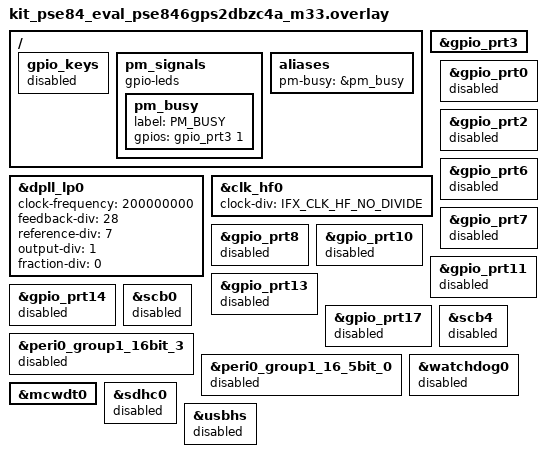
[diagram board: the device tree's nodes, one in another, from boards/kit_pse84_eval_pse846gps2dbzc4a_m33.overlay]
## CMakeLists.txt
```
cmake_minimum_required(VERSION 3.20.0)

# Register the app-local snippets/ dir so the `rram` snippet (used to
# link the image against the internal RRAM code region instead of the
# board-default SMIF XIP partition) is discoverable via
# `west build --snippet rram`. Must go BEFORE find_package(Zephyr) so
# snippets.cmake sees it during boilerplate include.
list(APPEND SNIPPET_ROOT ${CMAKE_CURRENT_SOURCE_DIR})

find_package(Zephyr REQUIRED HINTS $ENV{ZEPHYR_BASE})

project(pse84_m33_s_shell_ulp_lp_hp)

target_sources(app PRIVATE
    src/main.c
    src/power_manager.c
    src/power_manager_pll_retune.c
    src/power_manager_hf0_divider.c
    src/pm_phase_log.c
    src/pm_boot_optimize.c
    src/shell_cmds.c
    src/cmd_noidle.c
    src/cmd_sleep.c
    src/cmd_deep_sleep.c
    src/gpio_indicators.c
    src/diag.c
)

# When the `rram` snippet is selected, the SoC's signing helper
# (pse84_add_metadata_secure_hex) emits zephyr.signed.hex at the
# SMIF-SAHB base 0x60100000 for the m33-secure-only board variant
# (imgtool.py sign --hex-addr 0x60100000, derived from the board's
# `m33s_header` / `flash0_s` / `flash0_sahb` DT nodes).
# Rebase every IHEX extended-address record to RRAM-S 0x32011000
# (delta -0x2E0EF000) so OpenOCD's RRAM flash bank programs the
# correct memory. Payload bytes (vector table, MCUBoot header,
# hash, signature TLVs) are untouched, so SE-ROM signature
# verification still passes. Mirrors apps/00_hello_world, but note
# the base address differs by SoC variant: project 00 targets the
# m33/ns board where the signer picks 0x70100000; here we target
# the m33-secure-only board where it picks 0x60100000.
if("rram" IN_LIST SNIPPET_AS_LIST)
  set(_signed_hex ${ZEPHYR_BINARY_DIR}/${KERNEL_NAME}.signed.hex)
  set(_signed_hex_stamp ${_signed_hex}.rram.stamp)
  add_custom_command(
    OUTPUT ${_signed_hex_stamp}
    COMMAND ${CMAKE_COMMAND} -E echo
            "Shifting zephyr.signed.hex from SMIF-S 0x60100000 to RRAM-S 0x32011000"
    COMMAND ${CMAKE_OBJCOPY}
            --input-target=ihex
            --output-target=ihex
            --change-addresses=-0x2E0EF000
            ${_signed_hex}
            ${_signed_hex}.tmp
    COMMAND ${CMAKE_COMMAND} -E rename ${_signed_hex}.tmp ${_signed_hex}
    COMMAND ${CMAKE_COMMAND} -E touch ${_signed_hex_stamp}
    DEPENDS ${_signed_hex}
    COMMENT "Retargeting zephyr.signed.hex SMIF-S -> RRAM-S"
  )
  add_custom_target(retarget_signed_hex_to_rram ALL
    DEPENDS ${_signed_hex_stamp}
  )
endif()
```

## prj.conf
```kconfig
# Zephyr shell over the SCB UART console.
CONFIG_SHELL=y

# Shell serial backend: IRQ-driven RX. This lets the CPU stay in WFI
# indefinitely while waiting for a keypress, instead of polling the
# UART FIFO every CONFIG_SHELL_BACKEND_SERIAL_RX_POLL_PERIOD ms (10 ms
# default) which produces a visible 100 Hz spike train on the PPK2
# rail and keeps the "idle" baseline artificially elevated.
#
# HISTORICAL NOTE: an earlier revision of this project pinned the
# backend to CONFIG_SHELL_BACKEND_SERIAL_API_POLLING because the
# Infineon SCB UART driver's IRQ path spun forever on the first RX
# byte (Unhandled IRQn: 121 / bt_uart_isr hang, see
# doc/ifx_uart_driver_bug.md). That bug has since been fixed in
# zephyr/drivers/serial/uart_infineon_pdl.c
# (ifx_cat1_uart_irq_update now W1Cs RX_NOT_EMPTY and RX/TX error
# latches). The IRQ backend is now the correct choice.
CONFIG_UART_INTERRUPT_DRIVEN=y
CONFIG_SHELL_BACKEND_SERIAL_API_INTERRUPT_DRIVEN=y

# Enable the ARM idle-entry hook so the `noidle` shell command can
# veto WFI in the idle thread. When noidle is on, the CPU spin-loops
# through arch_cpu_idle() instead of sleeping -- lets us measure
# real active current at HP/LP/ULP, and gives the upcoming `sleep`
# command a non-sleeping baseline to compare against.
#
# ARM_ON_ENTER_CPU_IDLE_HOOK is a promptless symbol -- the app-local
# Kconfig defines APP_ENABLE_IDLE_HOOK which selects it.
CONFIG_APP_ENABLE_IDLE_HOOK=y

# Shell size trims to fit the 63 KB RRAM code region (rram snippet).
# We only need three top-level commands (hp / lp / ulp); help text,
# tab-completion, VT100 escapes and command history all cost ~1-2 KB
# each in RRAM and are not required for this demo.
CONFIG_SHELL_HELP=n
CONFIG_SHELL_HISTORY=n
CONFIG_SHELL_METAKEYS=n
CONFIG_SHELL_VT100_COMMANDS=n
CONFIG_SHELL_TAB=n
CONFIG_SHELL_TAB_AUTOCOMPLETION=n

# GPIO for the three on-board RGB indicator LEDs used by the shell
# handlers to signal the incoming mode before the SoC starts changing
# clocks / voltage.
CONFIG_GPIO=y

# Main stack: 4 KiB gives plenty of headroom for the LP/ULP transition
# code path which unrolls Cy_SysPm_SystemEnter{Hp,Lp,Ulp} + RRAM +
# ClkHf writes plus their PDL callback lists.
CONFIG_MAIN_STACK_SIZE=4096

# --- System timer ------------------------------------------------------
# Use the Infineon LPTIMER (MCWDT0 on PILO @ 32.768 kHz) as the Zephyr
# system clock instead of Cortex-M SysTick.
#
# SysTick is clocked from HF0 (the CPU clock), which this build
# reprograms per HP/LP/ULP mode (200 / 66 / 50 MHz). SysTick counts
# would then scale by the same ratio, making k_msleep / k_timer /
# k_cycle_get_32 report ~3-4x too long at LP/ULP -- see the (now
# retired) OPEN_systick_hf0_scaling.md analysis. MCWDT0 runs from
# PILO which is independent of every HF clock and stays alive through
# CPU deep sleep too, so it doubles as a deep-sleep wake source.
#
# The LPTIMER PDL driver (infineon_lp_timer_pdl.c) auto-enables via
# default y once mcwdt0 is 'okay' in DT. We just need to turn SysTick
# off so there is only one system-clock provider at link time.
CONFIG_CORTEX_M_SYSTICK=n
CONFIG_INFINEON_LP_TIMER_PDL=y
CONFIG_SYS_CLOCK_HW_CYCLES_PER_SEC=32768
```

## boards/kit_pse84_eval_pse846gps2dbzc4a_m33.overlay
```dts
/*
 * Copyright (c) 2026
 * SPDX-License-Identifier: Apache-2.0
 *
 * Minimal DT overlay for apps/06_pse84_m33_s_shell_ulp_lp_hp.
 *
 * Kept enabled (from the board common.dtsi / kit_pse84_eval_m33.dts):
 *   scb2 (uart2)              -> zephyr,console + zephyr,shell-uart
 *   peri0_group1_16bit_1      -> scb2 peripheral clock divider
 *   gpio_prt16                -> RGB LEDs (led0..led2 on P16.5-7)
 *   gpio_prt3                 -> pm_busy scope trigger on P3.1
 *   flash_controller / rram0  -> code storage (--snippet rram redirects
 *                                zephyr,flash here)
 *
 * Clock-tree baseline (see PLAN_dual_dvfs.md for full rationale)
 * ---------------------------------------------------------------
 * DPLL_LP0 is retuned to 200 MHz (from the board default 400 MHz)
 * and CLK_HF0 is set to divide-by-1, so:
 *
 *   DPLL_LP0 = 200 MHz
 *     |-- CLK_HF0  (/1)  = 200 MHz  -> CM33 core, AN237976 HP max
 *     `-- CLK_HF10 (/4)  =  50 MHz  -> SCB2 peripheral clock
 *
 * Reasons for this baseline:
 *   1. CM33 lands at exactly the AN237976 HP spec ceiling from boot,
 *      no runtime action needed.
 *   2. The maximum DPLL frequency ever seen at runtime is 200 MHz,
 *      safely inside DPLL_LP's 10-500 MHz spec at every voltage --
 *      the 400 MHz baseline previously flirted with the ULP-voltage
 *      lock hazard whenever the PLL-retune path had to reprogram
 *      it back up.
 *   3. Both DVFS approaches (PLL-retune and divider-only, see
 *      PLAN_dual_dvfs.md) share this same baseline so a switch
 *      between them is a code-only change.
 */

#include <zephyr/dt-bindings/clock/ifx_clock_source_common.h>

/ {
	/* Disable the gpio-keys container so the user button (P8.3)
	 * doesn't drag in gpio_prt8. The child node stays defined so
	 * DT_ALIAS(sw0) remains resolvable (evaluates disabled). */
	gpio_keys { status = "disabled"; };

	/* PM-transition scope trigger. P3.1 is driven high by the shell
	 * command layer while a mode change is in progress and low
	 * again once the transition (including SCB retune + clock
	 * probe) has completed. Wire a scope / logic-analyzer probe
	 * here to correlate current-draw waveforms with the actual
	 * software transition window. */
	pm_signals {
		compatible = "gpio-leds";
		pm_busy: pm_busy {
			label = "PM_BUSY";
			gpios = <&gpio_prt3 1 GPIO_ACTIVE_HIGH>;
		};
	};

	aliases {
		pm-busy = &pm_busy;
	};
};

/* Enable gpio_prt3 -- disabled at the SoC-dtsi level, but we need
 * it to drive the pm_busy scope trigger on P3.1 (see pm_signals
 * above). */
&gpio_prt3 { status = "okay"; };

/* ------------------------------------------------------------------
 * DPLL_LP0 -- retune the board default from 400 MHz to 200 MHz.
 *
 * Formula: output = input * feedback-div / (reference-div * output-div)
 * Input on this board is IHO = 50 MHz. Board default (400 MHz) uses
 * FB=56, REF=7, OUT=1 -> 50 * 56 / (7 * 1) = 400. Halving FB to 28
 * gives 50 * 28 / (7 * 1) = 200 MHz. Reference-div stays 7 to keep
 * the same phase-noise / jitter profile the board vendor selected.
 * ------------------------------------------------------------------ */
&dpll_lp0 {
	clock-frequency = <200000000>;
	feedback-div = <28>;
	reference-div = <7>;
	output-div = <1>;
	fraction-div = <0>;
};

&clk_hf0 {
	/* /1: DPLL_LP0 (200 MHz) -> CLK_HF0 200 MHz.
	 * Matches AN237976 CM33 HP frequency spec. The board default
	 * is /2 (was correct when DPLL was 400 MHz); we override to /1
	 * now that DPLL is at 200 MHz so the same baseline works for
	 * both DVFS approaches (see PLAN_dual_dvfs.md). */
	clock-div = <IFX_CLK_HF_NO_DIVIDE>;
};

/* ------------------------------------------------------------------
 * GPIO ports: keep only gpio_prt16 (RGB LEDs) and gpio_prt3 (see
 * the pm_signals node above -- P3.1 is the pm_busy scope trigger).
 * SCB2 pins (P6.5/P6.7) are routed by the pinctrl subsystem and do
 * NOT require the gpio_prt6 node to be enabled -- the pinctrl
 * driver programs HSIOM directly.
 * ------------------------------------------------------------------ */
&gpio_prt0  { status = "disabled"; };
&gpio_prt2  { status = "disabled"; };
&gpio_prt6  { status = "disabled"; };
&gpio_prt7  { status = "disabled"; };
&gpio_prt8  { status = "disabled"; };
&gpio_prt10 { status = "disabled"; };
&gpio_prt11 { status = "disabled"; };
&gpio_prt13 { status = "disabled"; };
&gpio_prt14 { status = "disabled"; };
&gpio_prt17 { status = "disabled"; };

/* ------------------------------------------------------------------
 * SCBs we don't use.
 * ------------------------------------------------------------------ */
&scb0 { status = "disabled"; };   /* i2c0 + bmi270 accelerometer   */
&scb4 { status = "disabled"; };   /* uart4 + bt_hci_uart + cyw55513 */

/* Their peripheral clock dividers -- also unused. */
&peri0_group1_16bit_3   { status = "disabled"; };  /* scb0 clock */
&peri0_group1_16_5bit_0 { status = "disabled"; };  /* scb4 clock */

/* ------------------------------------------------------------------
 * Timers, watchdogs, storage, connectivity we don't use.
 * ------------------------------------------------------------------ */
&watchdog0 { status = "disabled"; };

/* mcwdt0 is the Zephyr system-timer for this build (LPTIMER driver,
 * infineon_lp_timer_pdl.c). Runs off PILO @ 32.768 kHz, independent
 * of HF0, so k_msleep and k_cycle_get_32 do NOT scale with the
 * HP/LP/ULP mode -- fixes OPEN_systick_hf0_scaling.md. Also gives
 * `sleep` / `deep_sleep` shell commands a mode-independent wake
 * source (MCWDT keeps counting through CPU deep sleep too, because
 * PILO is a deep-sleep-alive clock). */
&mcwdt0    { status = "okay"; };
&sdhc0     { status = "disabled"; };   /* SDIO + airoc-wifi */
&usbhs     { status = "disabled"; };
```

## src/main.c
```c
/*
 * Copyright (c) 2026
 * SPDX-License-Identifier: Apache-2.0
 *
 * CM33-Secure shell-controlled active-power-mode demo -- bring-up.
 *
 * This file only handles application bring-up: print a banner,
 * initialise the GPIO indicators, initialise the power-mode
 * manager. Everything else lives in dedicated modules:
 *
 *   src/power_manager.[ch]   -- HP/LP/ULP transitions, PLL retune,
 *                               clock-measurement probe.
 *   src/shell_cmds.[ch]      -- ulp / lp / hp / probe shell
 *                               handlers.
 *   src/gpio_indicators.[ch] -- mode-indicator LEDs (led0 red,
 *                               led1 green) + PM-busy scope
 *                               trigger on P3.1.
 *   src/diag.[ch]            -- raw-SCB tracing, blue-LED
 *                               heartbeat thread (led2).
 *
 * The Zephyr shell auto-registers commands via SHELL_CMD_REGISTER
 * at link time, so pulling shell_cmds.c into the build is enough
 * to make the commands available.
 */

#include <stdio.h>

#include <zephyr/kernel.h>

#include "gpio_indicators.h"
#include "power_manager.h"

int main(void)
{
	printf("CM33-S shell-power-mode on %s\n", CONFIG_BOARD);

	if (gpio_indicators_init() < 0) {
		printf("CM33-S: GPIO indicators init failed\n");
		/* Non-fatal: shell + mode transitions still work; only
		 * the visual LED indicators and the P3.1 scope trigger
		 * are dark. */
	}

	pm_init();

	printf("CM33-S: initial power mode %s\n",
	       pm_mode_name(pm_current_mode()));
	return 0;
}
```

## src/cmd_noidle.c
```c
/*
 * Copyright (c) 2026
 * SPDX-License-Identifier: Apache-2.0
 */

/**
 * @file
 * @brief `noidle` shell command + Zephyr idle-hook to suppress WFI.
 *
 * Motivation: on this build the Zephyr idle thread runs
 * @c arch_cpu_idle() which normally does @c __WFI(). That means
 * "shell prompt idle" current on the PPK2 is already CPU-sleep
 * current -- WFI is happening whenever no thread has work.
 *
 * For a DVFS demo we sometimes want to see the OPPOSITE: what
 * does the SoC pull when the CM33 is genuinely executing code
 * (fetching, decoding, executing) at 200 / 80 / 50 MHz? That is
 * the delta the "sleep" command will reclaim, and without a way
 * to force the CPU into that state on demand there is nothing to
 * compare against.
 *
 * Zephyr exposes exactly this knob via @c CONFIG_ARM_ON_ENTER_CPU_IDLE_HOOK.
 * When enabled, the arch layer calls @c z_arm_on_enter_cpu_idle()
 * right before it would execute WFI. Returning @c false skips
 * WFI entirely -- the idle thread then just spin-loops through
 * @c arch_cpu_idle() returning immediately, and higher-priority
 * threads (or ISRs) still preempt as usual.
 *
 * Shell interface:
 *
 *   noidle          -- print current state ("on" or "off")
 *   noidle on       -- suppress WFI in idle. CPU runs continuously
 *                      at the current HP/LP/ULP mode clock rate.
 *                      PPK2 shows the real active current for
 *                      that mode.
 *   noidle off      -- restore normal WFI in idle. This is the
 *                      default state at boot. PPK2 shows the
 *                      sleep floor plus whatever the workqueue /
 *                      housekeeping wakes cost.
 *
 * Nothing else in this project queries the flag -- the hook is
 * the only consumer. Made @c atomic_t so a stray future concurrent
 * writer is well-defined; the hook itself runs from the idle
 * thread and cannot be preempted by another writer today.
 */

#include <zephyr/init.h>
#include <zephyr/kernel.h>
#include <zephyr/shell/shell.h>
#include <zephyr/sys/atomic.h>

#include <stddef.h>

/**
 * @brief When non-zero, @c z_arm_on_enter_cpu_idle returns false
 *        and the idle thread's WFI is skipped.
 */
static atomic_t s_prevent_idle;

/**
 * @brief ARM idle-entry hook (enabled by CONFIG_ARM_ON_ENTER_CPU_IDLE_HOOK).
 *
 * Called from @c arch_cpu_idle() with interrupts already disabled
 * via PRIMASK and BASEPRI set to 0. Return @c true to let the WFI
 * run (default), @c false to bypass it and return immediately.
 *
 * Keeping the check as a single atomic-read means no lock, no
 * branch predictor surprise, and the hook itself costs a handful
 * of cycles per idle entry -- negligible next to the WFI it
 * gates.
 */
bool z_arm_on_enter_cpu_idle(void)
{
	return atomic_get(&s_prevent_idle) == 0;
}

/**
 * @brief Shell handler for `noidle [on|off]`.
 *
 * With no argument, reports the current state. With "on" or
 * "off", sets it. Any other argument is a syntax error.
 */
static int cmd_noidle(const struct shell *sh, size_t argc, char **argv)
{
	if (argc == 1) {
		shell_print(sh, "noidle is %s",
			    (atomic_get(&s_prevent_idle) != 0) ? "on" : "off");
		return 0;
	}

	if (argc != 2) {
		shell_error(sh, "usage: noidle [on|off]");
		return -EINVAL;
	}

	if (strcmp(argv[1], "on") == 0) {
		atomic_set(&s_prevent_idle, 1);
		shell_print(sh, "noidle on -- CPU spins in idle (no WFI)");
		return 0;
	}
	if (strcmp(argv[1], "off") == 0) {
		atomic_set(&s_prevent_idle, 0);
		shell_print(sh, "noidle off -- WFI in idle (default)");
		return 0;
	}

	shell_error(sh, "usage: noidle [on|off]");
	return -EINVAL;
}

SHELL_CMD_REGISTER(noidle, NULL,
		   "Suppress WFI in idle thread. Use `noidle on` to see real "
		   "active current at the current HP/LP/ULP mode.",
		   cmd_noidle);
```

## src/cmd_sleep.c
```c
/*
 * Copyright (c) 2026
 * SPDX-License-Identifier: Apache-2.0
 */

/**
 * @file
 * @brief `sleep` shell command -- put CM33 into CPU-sleep (WFI) until
 *        the next NVIC IRQ (typically a UART RX character).
 *
 * Motivation: with `noidle on` the CPU spin-loops in idle and pulls
 * the mode's real active current (HP 5.36 / LP 2.34 / ULP 1.54 mA
 * measured). Running an explicit `sleep` puts the core into WFI on
 * demand and drops the current back to the sleep floor (HP 3.34 /
 * LP 1.73 / ULP 1.16 mA measured) until a keypress. Together with
 * `noidle`, the pair gives an on-demand active-vs-sleep A/B
 * measurement without waiting for Zephyr's idle thread to decide.
 *
 * Cycle instrumentation: reads @c k_cycle_get_32 (which on this SoC
 * is @c Cy_MCWDT_GetCountCascaded (counter2 @ 50 MHz LPTIMER)) both
 * sides of the @c __WFI. The delta is wall-clock time -- the CPU
 * pipeline was stopped, but the LPTIMER runs off HF10 (independent
 * of HF0). This is the number PPK2's D7 sees as the sleep window
 * width.
 *
 * pm-busy GPIO framing so external post-processing (PPK2 + D7 line)
 * can locate the WFI window automatically:
 *
 *   pm-busy HIGH       cmd running (banner print + TX drain, ~20 ms)
 *   pm-busy LOW        WFI window (variable duration -- user waits,
 *                                  presses key, chip wakes)
 *   pm-busy HIGH       post-wake (elapsed print, ~1 ms)
 *   pm-busy LOW        back to shell prompt
 *
 * IRQ prologue mirrors tmp/16_pse84_3img_rram_pm/m33_ns/src/power.c:
 * PRIMASK on, BASEPRI off, so the CPU still wakes on any enabled
 * NVIC source but interrupts don't actually take (they just pend
 * and get serviced after __enable_irq). Without this, WFI can
 * either miss the wake (BASEPRI masks the source out) or run the
 * ISR mid-instrumentation (jitters the cycle count).
 *
 * Break-even relative to `noidle on`:
 *   The entry/exit overhead is dominated by shell_print + k_msleep
 *   (tens of ms) which is a demo-only cost. The interesting number
 *   is the WFI entry/exit itself: on Cortex-M33 that is a handful
 *   of CPU cycles either side of the instruction (order 10 ns at
 *   200 MHz). At any HP/LP/ULP active-vs-sleep delta above ~0.4 mA,
 *   break-even is under 1 us. That is: any sleep window longer than
 *   ~1 us is a net energy win. Post-processing table quantifies
 *   this per mode.
 */

#include <zephyr/kernel.h>
#include <zephyr/shell/shell.h>
#include <zephyr/sys/time_units.h>

#include <cmsis_core.h>
#include <cy_sysclk.h>

#include <stddef.h>

#include "gpio_indicators.h"

/**
 * @brief Shell handler for `sleep`.
 *
 * Blocks the shell thread on WFI until the next NVIC interrupt.
 * The chip's UART RX IRQ is enabled and unmasked, so any character
 * typed in the terminal wakes the CPU. Other enabled ISRs
 * (LPTIMER, workqueue) may also wake spuriously; the printed
 * duration lets the user distinguish "keypress wake" (100+ ms) from
 * "housekeeping wake" (~80 ms periodic on this build).
 */
static int cmd_sleep(const struct shell *sh, size_t argc, char **argv)
{
	ARG_UNUSED(argc);
	ARG_UNUSED(argv);

	/* Mark: sleep command is running (pm-busy HIGH). */
	gpio_indicators_transition_begin();

	shell_print(sh, "entering CPU sleep -- press any key to wake");

	/* Let the shell TX ring drain before WFI. In IRQ-driven mode
	 * the TX-empty IRQ would spuriously wake us mid-drain; a
	 * short sleep here yields to that IRQ path via the idle
	 * thread (which itself still WFIs -- noidle only affects
	 * arch_cpu_idle, not k_sleep) and returns once the shell TX
	 * is quiescent. 20 ms is enough for ~200 chars at 115200 8N1. */
	k_msleep(20);

	/* Mark: about to WFI (pm-busy HIGH -> LOW). Post-processing
	 * uses this falling edge as the sleep-window start. */
	gpio_indicators_transition_end();

	uint32_t t_enter = k_cycle_get_32();

	/* PRIMASK on, BASEPRI off -- see file-level comment. */
	__disable_irq();
	irq_unlock(0);
	__DSB();
	__WFI();
	__enable_irq();

	uint32_t t_exit = k_cycle_get_32();

	/* Mark: woke up (pm-busy LOW -> HIGH). Post-processing uses
	 * this rising edge as the sleep-window end. */
	gpio_indicators_transition_begin();

	uint32_t dwell_cyc = t_exit - t_enter;

	/* IMPORTANT: k_cycle_get_32 reads Cortex-M SysTick, which is
	 * clocked from HF0 (the CPU clock). This build reprograms HF0
	 * per mode (HP=200 / LP=66 / ULP=50 MHz), but Zephyr's
	 * CONFIG_SYS_CLOCK_HW_CYCLES_PER_SEC is a compile-time constant
	 * baked at HP. Using k_cyc_to_us_floor32 here would mis-report
	 * dwell by up to 4x. Convert against the LIVE HF0 frequency
	 * instead, read from the PDL at print time.
	 *
	 * Broader impact (not fixed here): every Zephyr timer function
	 * -- k_msleep, k_sleep, k_timer, thread timeouts -- is scaled
	 * by the same wrong factor at LP/ULP. That is why the
	 * "mysterious 80 ms periodic wake" observed at LP is really
	 * Zephyr's ~26 ms housekeeping tick stretched by the HF0
	 * ratio. Fix belongs in the system-timer selection (use
	 * MCWDT0/LPTIMER on HF10 which is constant across modes).
	 * Tracked separately. */
	uint32_t hf0_hz = Cy_SysClk_ClkHfGetFrequency(0U);
	uint32_t dwell_us =
	    (uint32_t)(((uint64_t)dwell_cyc * 1000000U) / hf0_hz);

	shell_print(sh, "woke after %u us (%u cycles @ live HF0 = %u Hz)",
		    dwell_us, dwell_cyc, hf0_hz);

	/* Mark: shell prompt returning (pm-busy HIGH -> LOW). */
	gpio_indicators_transition_end();
	return 0;
}

SHELL_CMD_REGISTER(sleep, NULL,
		   "Enter CPU sleep (WFI) until any NVIC IRQ (e.g. UART RX). "
		   "Prints wall-clock dwell on wake. Pair with `noidle on` "
		   "to see the active-vs-sleep current delta.",
		   cmd_sleep);
```

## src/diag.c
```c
/*
 * Copyright (c) 2026
 * SPDX-License-Identifier: Apache-2.0
 *
 * See diag.h for the diagnosis matrix and rationale.
 */

#include "diag.h"

#include <stdint.h>

#include <zephyr/device.h>
#include <zephyr/drivers/gpio.h>
#include <zephyr/kernel.h>

/*
 * SCB2 register block base. Hard-coded rather than derived from DT
 * because we deliberately want to poke this SCB even when the Zephyr
 * driver's cached configuration might be broken.
 *
 * PSE84 exposes SCB2 through two AHB aliases; the correct one depends
 * on the security state of the accessing bus master:
 *
 *   Non-Secure alias (M33-NS / M55-NS code):  0x429a0000
 *   Secure     alias (M33-S code):            0x529a0000
 *
 * This project builds for `kit_pse84_eval/pse846gps2dbzc4a/m33` (the
 * Secure-only board variant, CONFIG_TRUSTED_EXECUTION_SECURE=y), so
 * we MUST use the Secure alias. Writing the NS alias from Secure
 * code raises a BusFault (\"peripheral not accessible from current
 * security state\") that escalates to HardFault -- observed as the
 * whole CPU freezing on the very first diag_trace() call, the
 * heartbeat thread never getting to run, and no bytes on the wire.
 *
 * The pse84_s.dtsi node confirms the mapping:
 *   scb2: scb@529a0000 { reg = <0x529a0000 0xfd0>; ... }
 *
 * Note: the reference implementation
 * `tmp/zephyr_dvfs_dpm_proposed/common/pse84_aliases.h` hard-codes
 * 0x429a0000 because that project's raw-console lives in CM33-NS.
 *
 * SCB register offsets from Infineon `pdl/devices/include/ip/cyip_scb.h`
 * (verified: TX_FIFO_STATUS at 0x208, TX_FIFO_WR at 0x240 -- these
 * are IP-version-stable on the PSE84 SCB v3):
 *   TX_FIFO_STATUS  0x208   bits[8:0]  = USED entry count
 *                           bit  15    = SR_VALID (TX shift reg has a byte)
 *   TX_FIFO_WR      0x240   write here to enqueue a byte
 *
 * Earlier revisions of this file tried to use INTR_TX.UART_DONE
 * (offset 0xF80, bit 9) for the "TX complete" check. UART_DONE is a
 * LATCHED interrupt bit -- it only re-asserts on the transition
 * from "TX busy" to "TX idle". If the FIFO is already empty when
 * diag_trace_flush() is called (which is the norm at the end of
 * pm_switch_to, because pm_pll_reconfigure() flushed inside the
 * callback and nothing else was queued in the meantime), UART_DONE
 * never transitions and the flush spins forever, freezing the
 * console.
 *
 * TX_FIFO_STATUS.{USED, SR_VALID} are STATE bits, not latches --
 * safe to poll unconditionally. This mirrors the PDL helper
 * Cy_SCB_IsTxComplete() which uses exactly these two fields.
 */
#define APP_SCB2_BASE 0x529a0000u
#define APP_SCB2_TX_FIFO_STATUS (*(volatile uint32_t *)(APP_SCB2_BASE + 0x208u))
#define APP_SCB2_TX_FIFO_WR (*(volatile uint32_t *)(APP_SCB2_BASE + 0x240u))

/* From cyip_scb.h SCB_TX_FIFO_STATUS_{USED,SR_VALID}_Msk -- exposed
 * here as local constants so the raw-SCB path stays completely
 * independent of the PDL. */
#define APP_SCB2_TX_FIFO_STATUS_USED_Msk 0x000001FFu
#define APP_SCB2_TX_FIFO_STATUS_SR_VALID_Msk 0x00008000u

/*
 * SCB v3 TX FIFO on PSE84 is 256 entries deep, but the block is
 * initialised with a smaller effective depth. Waiting until USED
 * drops below 16 leaves plenty of headroom and matches the reference
 * implementation's threshold.
 */
#define APP_SCB2_TX_FIFO_HEADROOM 16u

void diag_trace_char(char c)
{
	while ((APP_SCB2_TX_FIFO_STATUS & APP_SCB2_TX_FIFO_STATUS_USED_Msk) >=
	       APP_SCB2_TX_FIFO_HEADROOM) {
		/* spin — wait for TX FIFO room */
	}
	APP_SCB2_TX_FIFO_WR = (uint32_t)(uint8_t)c;
}

void diag_trace(const char *s)
{
	if (s == NULL) {
		return;
	}
	while (*s != '\0') {
		if (*s == '\n') {
			diag_trace_char('\r');
		}
		diag_trace_char(*s);
		s++;
	}
}

void diag_trace_flush(void)
{
	/* Wait until both the TX FIFO and the shift register are empty.
	 * Both fields live in TX_FIFO_STATUS -- one register read per
	 * loop iteration. Naturally returns immediately if the SCB is
	 * already idle, because both fields are true state (not latches
	 * that need a fresh transition to re-arm). Equivalent to the
	 * PDL's Cy_SCB_IsTxComplete(). */
	const uint32_t busy_mask = APP_SCB2_TX_FIFO_STATUS_USED_Msk |
				   APP_SCB2_TX_FIFO_STATUS_SR_VALID_Msk;

	while ((APP_SCB2_TX_FIFO_STATUS & busy_mask) != 0u) {
		/* spin */
	}
}

/*
 * Heartbeat thread ---------------------------------------------------
 *
 * Owns led2 (blue) exclusively so its blink rate is a pure indicator
 * of CPU liveness. Independent of console, Zephyr shell backend, and
 * any mode-transition side-effect. If the blue LED continues blinking
 * at ~2 Hz after a console "freeze", the CPU is still executing
 * scheduled threads — the fault must be in the console path (Zephyr
 * shell task, SCB UART driver, or the shell's ring-buffer).
 *
 * Uses a low-priority preemptible thread so it never starves the
 * shell RX / TX handlers. Cooperative would be fine too but we keep
 * it preemptible for identical behaviour under HP/LP/ULP.
 */
static const struct gpio_dt_spec led_heartbeat =
    GPIO_DT_SPEC_GET(DT_ALIAS(led2), gpios);

#define HEARTBEAT_STACK_SIZE 512
#define HEARTBEAT_PRIORITY 10 /* preemptible, well below shell */

static void heartbeat_entry(void *a, void *b, void *c)
{
	ARG_UNUSED(a);
	ARG_UNUSED(b);
	ARG_UNUSED(c);

	if (!gpio_is_ready_dt(&led_heartbeat)) {
		return;
	}
	(void)gpio_pin_configure_dt(&led_heartbeat, GPIO_OUTPUT_INACTIVE);

	for (;;) {
		(void)gpio_pin_toggle_dt(&led_heartbeat);
		k_msleep(500);
	}
}

K_THREAD_DEFINE(heartbeat_tid, HEARTBEAT_STACK_SIZE, heartbeat_entry, NULL,
		NULL, NULL, HEARTBEAT_PRIORITY, 0, 0);
```

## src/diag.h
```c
/*
 * Copyright (c) 2026
 * SPDX-License-Identifier: Apache-2.0
 *
 * Diagnostics layer for pinpointing HP/LP/ULP freeze mode.
 *
 * We use raw SCB2 register pokes (bypassing Zephyr's Infineon SCB UART
 * driver) so that trace output survives even if the driver's cached
 * baud divider is invalidated by a mode transition. A companion
 * heartbeat thread toggles the blue LED at 2 Hz so a human observer
 * can tell CPU-alive from CPU-hung without any terminal at all.
 *
 * Interpretation matrix after a "freeze" event:
 *
 *   BLUE LED        RAW TRACE MARKERS       DIAGNOSIS
 *   --------------------------------------------------------------
 *   still blinking  streaming after freeze  CPU + UART alive;
 *                                           Zephyr shell task stuck
 *   still blinking  stop at freeze          CPU alive; SCB UART dead
 *   frozen          stop at freeze          Hard CPU hang
 *
 * The raw-SCB path polls @c TX_FIFO_STATUS.USED (bits [8:0], 9 bits
 * wide per the SCB v3 IP) and treats >= 16 as "wait". SCB2 is
 * accessed via its Secure alias 0x529a0000 -- we build for the
 * secure-only board variant, so writing the Non-Secure alias
 * 0x429a0000 (which the reference project's raw console uses
 * because it runs from CM33-NS) would raise a BusFault.
 */
#ifndef APP_DIAG_H_
#define APP_DIAG_H_

#include <stddef.h>

/**
 * @brief Push a single byte into SCB2's TX FIFO, spinning until the
 *        FIFO has space. Bypasses the Zephyr UART driver entirely so
 *        it keeps working even if `uart_configure()` is broken.
 */
void diag_trace_char(char c);

/**
 * @brief Push a NUL-terminated string via @ref diag_trace_char, LF
 *        translated to CRLF for terminal-friendly newlines.
 */
void diag_trace(const char *s);

/**
 * @brief Block until the SCB2 TX FIFO AND the TX shift register are
 *        fully drained.
 *
 * Call this immediately before any operation that changes the SCB2
 * peripheral clock (e.g. @c Cy_SysClk_PllDisable in
 * @c pm_pll_reconfigure). Any byte still sitting in the TX FIFO or
 * the shift register when the clock changes will be shifted out at
 * the new/fallback bit-time, producing the corrupted-mid-string
 * output that was visible on the console before this call was
 * added.
 *
 * Cheap and safe -- polls two SCB registers, no locking, no calls
 * into the Zephyr driver.
 */
void diag_trace_flush(void);

#endif /* APP_DIAG_H_ */
```

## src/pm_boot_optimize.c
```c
/*
 * Copyright (c) 2026
 * SPDX-License-Identifier: Apache-2.0
 */

/**
 * @file
 * @brief One-shot boot-time trimming of unused SoC subsystems.
 *
 * PSE84 RRAMboot leaves the whole HFCLK tree enabled (HF0..HF13
 * confirmed via util/dump_hfclk.sh), both SMIF controllers active,
 * the SOCMEM controller powered, and every APP-domain PPU in the
 * ON state -- even though this Secure-only demo uses only the CM33
 * core, DPLL_LP0 (feeding CLK_HF0 for the core and CLK_HF10 for
 * SCB2), a handful of GPIO pins, and the RRAM controller.
 *
 * All that extra silicon appears as a constant offset in every
 * PPK2 measurement. This file runs once at APPLICATION init
 * (@c SYS_INIT priority 0), before @c main(), and gates every
 * subsystem the demo does not touch:
 *
 *   1. SOCMEM controller off             (Cy_SysEnableSOCMEM)
 *   2. Both SMIF cores off               (CTL.ENABLED cleared)
 *   3. APP power domain (PD1) collapsed  (PPUs -> OFF)
 *   4. HF1..HF9 + HF11..HF13 gated       (Cy_SysClk_ClkHfDisable)
 *   5. DPLL_LP1 + DPLL_HP disabled       (Cy_SysClk_Dpll*Disable)
 *   6. GPIO ports we don't drive         (Cy_GPIO_Port_Deinit)
 *
 * Everything the demo NEEDS is deliberately left alone:
 *   - HF0        -- CM33 core clock
 *   - HF10       -- SCB2 UART peripheral clock
 *   - DPLL_LP0   -- HF0/HF10 source (retuned by PLL_RETUNE)
 *   - GPIO P3    -- pm_busy scope trigger
 *   - GPIO P16   -- RGB LEDs
 *
 * What we deliberately do NOT do (would break the demo):
 *   - Disable DPLL_LP0                (needed by PLL_RETUNE)
 *   - Enter SystemUlp profile at boot (caps HF0 <= 50 MHz, breaks
 *                                      HP mode)
 *   - Disable the debug session       (blocks re-flash without XRES,
 *                                      kills the KitProg CDC UART)
 *   - Gate peri-group slave clocks    (would need per-group audit of
 *                                      which SCB / GPIO / HSIOM slice
 *                                      we still depend on -- HF1..HF9
 *                                      gating already kills their
 *                                      clock source anyway)
 *
 * Inspired by tmp/app_pm_boot.c from the deep-sleep reference
 * project. This is the runtime-active analogue: same set of
 * subsystems shut down, but WITHOUT the ULP-profile / debug
 * disable / DS-RAM PPU targets that would make the demo unusable.
 */

#include <zephyr/init.h>

#include <soc.h>

#include "cy_gpio.h"
#include "cy_pdl.h"
#include "cy_sysclk.h"
#include "cy_syspm.h"
#include "cy_syspm_pdcm.h"
#include "cy_syspm_ppu.h"
#include "system_edge.h"

#include <zephyr/sys/printk.h>

/** Number of GPIO port peripherals on PSE84 (P0..P21). */
#define PSE84_GPIO_PORT_COUNT 22u

/** GPIO ports the demo keeps live -- everything else gets
 *  Cy_GPIO_Port_Deinit. */
#define KEEP_PORT_PM_BUSY 3u /* P3.1 -- pm-busy scope trigger. */
#define KEEP_PORT_LEDS 16u   /* P16.5/6/7 -- RGB LEDs. */

/** HFCLK indices this build never uses. HF0 and HF10 are
 *  deliberately absent: HF0 is the CM33 core clock, HF10 is the
 *  SCB2 UART clock. HF1 (APPCPUSS) and HF2 (SOCMEM PPU / DPLL_HP)
 *  are included -- the "must complete PPU Q-channel handshake
 *  first" caveat from tmp/app_pm_boot.c only matters for deep-sleep
 *  entry; in active runtime, gating them idles the block with no
 *  side-effect because CM55 is never booted and SOCMEM was already
 *  disabled above. */
static const uint8_t s_unused_hf_clocks[] = {
    1,	/* HF1  -- APPCPUSS, APP_MMIO[0..4], PERI_1 group 0  */
    2,	/* HF2  -- SOCMEM, PERI_1 group 5                    */
    3,	/* HF3  -- SMIF0                                     */
    4,	/* HF4  -- SMIF1                                     */
    5,	/* HF5  -- SDHC0, PERI_0 group 3, PERI_1 group 2     */
    6,	/* HF6  -- SDHC1, PERI_0 group 4, PERI_1 group 3  */
    7,	/* HF7  -- PDM, PERI_1 group 1 (fed by DPLL_LP1)  */
    8,	/* HF8  -- USB                                    */
    9,	/* HF9  -- SYS_MMIO[5], Autonomous Analog         */
    11, /* HF11 -- SYS_MMIO[3], SCB[1], PERI_0 group 8    */
    12, /* HF12 -- MIPI-DSI D-PHY PLL reference           */
    13, /* HF13 -- I3C, PERI_0 group 6/9                  */
};

/**
 * @brief Disable the on-chip SOCMEM controller.
 *
 * SOCMEM is a 2 MB shared memory that only CM55 uses; this
 * Secure-only CM33 build never touches it. Boot ROM leaves the
 * block powered so the CM55 can boot into it; we don't need
 * that.
 */
static void trim_socmem(void) { Cy_SysEnableSOCMEM(false); }

/**
 * @brief Disable both Serial Memory Interface controllers.
 *
 * Boot ROM configures SMIF0 for QSPI XIP; this build runs from
 * internal RRAM instead (see snippets/rram/) and never issues an
 * SMIF transaction. Clearing @c CTL.ENABLED stops the block
 * clocks and puts its output pads high-Z.
 *
 * Direct register write to avoid pulling @c cy_smif.h (and its
 * transitive dependencies) into the build.
 */
static void trim_smif(void)
{
	SMIF0_CORE->CTL &= ~SMIF_CORE_CTL_ENABLED_Msk;
	SMIF1_CORE->CTL &= ~SMIF_CORE_CTL_ENABLED_Msk;
}

/**
 * @brief Collapse the APP power domain (PD1) via its PPUs.
 *
 * PSE84 splits the SoC into two hard power domains:
 *   PD0 (SYS): SYSCPU (CM33), SYS_MMIO*, RRAM, SRSS, BACKUP.
 *   PD1 (APP): APPCPU (CM55), APPCPUSS, U55 (NPU), SOCMEM, plus
 *              their MMIO bridges (APP_MMIO0..4).
 *
 * This build uses ONLY the CM33 in PD0. Everything in PD1 is
 * dead code -- CM55 is never booted, U55 is never used, SOCMEM
 * was already gated via @c trim_socmem above. But RRAMboot
 * leaves every PD1 PPU in the ON state (so a debugger could
 * poke around before CM55 boots), which keeps the whole APP
 * rail powered.
 *
 * Requesting @c PPU_V1_MODE_OFF on the four APP PPUs plus PD1
 * itself tells the arm-controller Q-channel to collapse each
 * block as soon as its dependents are quiescent. Two things
 * have to happen first for the collapse to actually complete:
 *
 *   (a) Clear the boot-ROM-installed PDCM edge that lists
 *       APPCPUSS as a hard dependent of SYSCPU. Without this
 *       our CM33 (SYSCPU=ON) forever pins APPCPUSS=ON.
 *
 *   (b) Detach the CM55 debug AP via @c Cy_SysCM55SetDbgPort.
 *       RRAMboot leaves @c APPCPUSS->AP_CTL asserting the CM55
 *       DAP enables; an enabled DAP is a hardware requestor on
 *       APPCPU's domain even without a debugger physically
 *       attached, which pins APPCPU=ON. Clearing AP_CTL is the
 *       moral equivalent of the SDK's DS-RAM path (which
 *       actually boots CM55, tells it to WFI, and lets the
 *       Q-channel see it drop). We take the cheaper route --
 *       just yank the DAP.
 *
 * We do NOT touch the SYSCPU PPU (PD0). CM33 is running out of
 * that domain; putting it OFF would be self-destructive.
 *
 * Must run BEFORE @c trim_unused_hf_clocks. The Q-channel
 * handshake between the PPU and its slave interfaces uses HF1
 * (APPCPUSS clock) and HF2 (SOCMEM PPU clock). If we gate those
 * first, the handshake stalls and the PPU is stuck in a chimera
 * state (PWPR=OFF requested, PWSR still ON). Reference firmware
 * enforces the same ordering.
 */
static void trim_app_domain(void)
{
	struct ppu_v1_reg *ppu_pd1 = (struct ppu_v1_reg *)CY_PPU_PD1_BASE;
	struct ppu_v1_reg *ppu_socmem = (struct ppu_v1_reg *)CY_PPU_SOCMEM_BASE;
	struct ppu_v1_reg *ppu_appcpuss =
	    (struct ppu_v1_reg *)CY_PPU_APPCPUSS_BASE;
	struct ppu_v1_reg *ppu_appcpu = (struct ppu_v1_reg *)CY_PPU_APPCPU_BASE;
	struct ppu_v1_reg *ppu_u55 = (struct ppu_v1_reg *)CY_PPU_U55_BASE;

	/* (a) Break the boot-ROM PDCM edge SYSCPU->APPCPUSS. */
	(void)cy_pd_pdcm_clear_dependency(CY_PD_PDCM_APPCPUSS,
					  CY_PD_PDCM_SYSCPU);

	/* (b) Drop the CM55 debug AP so APPCPU can quiesce. */
	Cy_SysCM55SetDbgPort(APPCPUSS_DBG_DISABLE);

	/* Request OFF on parent first, then children. Actual
	 * sequencing is enforced by the Q-channel handshake, not
	 * by these register writes. */
	(void)cy_pd_ppu_set_power_mode(ppu_pd1, (uint32_t)PPU_V1_MODE_OFF);
	(void)cy_pd_ppu_set_power_mode(ppu_socmem, (uint32_t)PPU_V1_MODE_OFF);
	(void)cy_pd_ppu_set_power_mode(ppu_appcpuss, (uint32_t)PPU_V1_MODE_OFF);
	(void)cy_pd_ppu_set_power_mode(ppu_appcpu, (uint32_t)PPU_V1_MODE_OFF);
	(void)cy_pd_ppu_set_power_mode(ppu_u55, (uint32_t)PPU_V1_MODE_OFF);
}

/**
 * @brief Gate every HFCLK root the demo does not use.
 *
 * Uses @c Cy_SysClk_ClkHfDisable which stops the root's output
 * clock. Downstream peripherals of a gated HF root cannot run,
 * but every downstream peripheral here is one we've already
 * confirmed unused (SMIF0/1, SDHC0/1, PDM, USB, MIPI-DSI, I3C,
 * SCB[1], plus the SYS_MMIO[3..5] bridges).
 */
static void trim_unused_hf_clocks(void)
{
	for (size_t i = 0; i < ARRAY_SIZE(s_unused_hf_clocks); i++) {
		(void)Cy_SysClk_ClkHfDisable(s_unused_hf_clocks[i]);
	}
}

/**
 * @brief Deinit every GPIO port except the two we drive.
 *
 * A GPIO port left at its RRAMboot default may have input
 * buffers active on floating pins, drawing tens of uA per pin.
 * @c Cy_GPIO_Port_Deinit resets the whole port to high-Z analog:
 * HSIOM disconnected, output-drive mode disabled, input buffer
 * off.
 *
 * We keep P3 (P3.1 = pm_busy scope trigger) and P16 (P16.5/6/7 =
 * RGB LEDs) untouched.
 */
static void trim_unused_gpio_ports(void)
{
	for (uint32_t port = 0u; port < PSE84_GPIO_PORT_COUNT; port++) {
		if (port == KEEP_PORT_PM_BUSY || port == KEEP_PORT_LEDS) {
			continue;
		}
		GPIO_PRT_Type *prt =
		    (GPIO_PRT_Type *)(CY_GPIO_BASE +
				      (port * GPIO_PRT_SECTION_SIZE));
		Cy_GPIO_Port_Deinit(prt);
	}
}

/**
 * @brief Disable DPLL_LP1 and DPLL_HP.
 *
 * After @c trim_unused_hf_clocks gates HF1..HF9 and HF11..HF13:
 *   - DPLL_LP1 has no downstream (HF7 was its only consumer)
 *   - DPLL_HP  has no downstream (HF2 was its only consumer)
 *
 * A powered-on PLL block that no HFCLK routes through still draws
 * bias current -- disabling the block itself saves that. Must run
 * AFTER @c trim_unused_hf_clocks so the ordering guarantees no
 * downstream HFCLK loses its source mid-use.
 *
 * DPLL_LP0 is deliberately left alone -- HF0 (CM33 core) and HF10
 * (SCB2 UART) both feed from it, and PM_STRATEGY_PLL_RETUNE
 * reprograms it around every DVFS transition.
 */
static void trim_unused_plls(void)
{
	(void)Cy_SysClk_DpllLpDisable(1);
	(void)Cy_SysClk_DpllHpDisable(0);
}

/**
 * @brief Boot hook -- runs once at APPLICATION init, before main().
 *
 * Order matters between three adjacent pairs:
 *   - trim_socmem must precede trim_app_domain (the SOCMEM
 *     controller and its PPU are two independent power controls;
 *     stopping the controller first quiesces its Q-channel so the
 *     PPU collapse doesn't stall)
 *   - trim_app_domain must precede trim_unused_hf_clocks (PPU
 *     Q-channel handshake needs HF1 (APPCPUSS) and HF2 (SOCMEM
 *     PPU) alive; gating them first stalls the collapse)
 *   - trim_unused_hf_clocks must precede trim_unused_plls (PLLs
 *     only safely disable after their last downstream HFCLK is
 *     gated)
 * The remaining helpers are independent -- ordering here just
 * follows "coarse to fine" for readability.
 */
static int pm_boot_optimize(void)
{
	trim_socmem();
	trim_smif();
	trim_app_domain();
	trim_unused_hf_clocks();
	trim_unused_plls();
	trim_unused_gpio_ports();
	printk("[pm-boot] trimmed SOCMEM, SMIF0/1, PD1 (APP domain), "
	       "HF{1..9,11..13}, DPLL_LP1, DPLL_HP, "
	       "GPIO ports (kept 3, 16)\n");
	return 0;
}

SYS_INIT(pm_boot_optimize, APPLICATION, 0);

/**
 * @brief Preemptively disable MCWDT0 counters so the Zephyr LPTIMER
 *        driver's init succeeds.
 *
 * The Infineon LPTIMER driver (@c infineon_lp_timer_pdl.c, SYS_INIT
 * at PRE_KERNEL_2) calls @c Cy_MCWDT_Init which returns BAD_PARAM if
 * any counter is already enabled. SE-ROM / RRAM boot leaves MCWDT0
 * counters running on cold boot, so without a preemptive disable the
 * driver's @c lptimer_init returns @c -EINVAL, the system clock
 * never starts, and @c k_msleep / @c k_busy_wait hang forever
 * (@c sys_clock_cycle_get_32 reads a counter that never advances).
 *
 * SYS_INIT failures do NOT abort boot in Zephyr, so the symptom is
 * silent: banner prints, then the first sleep-related call spins
 * forever. Mirrors the ifx_pm_init workaround in
 * tmp/16_pse84_3img_rram_pm/m33_ns/src/power.c.
 *
 * Runs at PRE_KERNEL_1 priority 0 -- earliest possible slot -- so
 * the counters are always clean by the time the LPTIMER PDL driver
 * runs at PRE_KERNEL_2.
 */
static int pm_early_mcwdt_reset(void)
{
	Cy_MCWDT_Unlock(MCWDT_STRUCT0);
	Cy_MCWDT_Disable(MCWDT_STRUCT0,
			 CY_MCWDT_CTR0 | CY_MCWDT_CTR1 | CY_MCWDT_CTR2, 100U);
	Cy_MCWDT_ClearInterrupt(MCWDT_STRUCT0,
				CY_MCWDT_CTR0 | CY_MCWDT_CTR1 | CY_MCWDT_CTR2);
	Cy_MCWDT_SetInterruptMask(MCWDT_STRUCT0, 0U);
	return 0;
}

SYS_INIT(pm_early_mcwdt_reset, PRE_KERNEL_1, 0);
```

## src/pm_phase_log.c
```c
/*
 * Copyright (c) 2026
 * SPDX-License-Identifier: Apache-2.0
 */

/**
 * @file
 * @brief Implementation of the per-transition phase log.
 * See @c pm_phase_log.h for the interface contract.
 */

#include "pm_phase_log.h"

#include <stdint.h>

#include <zephyr/sys/printk.h>

/* Sized for the strategy with the most phases -- currently PLL_RETUNE
 * with three (pll_pre, volt, pll_post). Bump if a future strategy
 * needs finer granularity. */
#define PM_PHASE_LOG_MAX_PHASES 8

static uint32_t s_cycles[PM_PHASE_LOG_MAX_PHASES];
static uint32_t s_hz[PM_PHASE_LOG_MAX_PHASES];
static const char *s_names[PM_PHASE_LOG_MAX_PHASES];
static uint8_t s_count;
static const char *s_label = "";

static inline uint32_t entry_us(uint8_t i)
{
	uint32_t hz = (s_hz[i] != 0u) ? s_hz[i] : 1u;

	return (uint32_t)(((uint64_t)s_cycles[i] * 1000000ULL) / hz);
}

void pm_phase_log_reset(const char *label)
{
	s_label = (label != NULL) ? label : "";
	s_count = 0u;
}

void pm_phase_log_record(const char *name, uint32_t cycles, uint32_t hz)
{
	if (s_count < PM_PHASE_LOG_MAX_PHASES) {
		s_names[s_count] = (name != NULL) ? name : "?";
		s_cycles[s_count] = cycles;
		s_hz[s_count] = hz;
		s_count++;
	}
}

void pm_phase_log_print(void)
{
	uint32_t total_us = 0u;
	uint8_t i;

	if (s_count == 0u) {
		return;
	}
	printk("[pm] %s phases:", s_label);
	for (i = 0u; i < s_count; i++) {
		uint32_t us = entry_us(i);

		total_us += us;
		printk(" %s=%uus", s_names[i], us);
	}
	printk(" total=%uus\n", total_us);
}

uint32_t pm_phase_log_total_us(void)
{
	uint32_t total_us = 0u;
	uint8_t i;

	for (i = 0u; i < s_count; i++) {
		total_us += entry_us(i);
	}
	return total_us;
}
```

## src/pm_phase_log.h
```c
/*
 * Copyright (c) 2026
 * SPDX-License-Identifier: Apache-2.0
 */

/**
 * @file
 * @brief Small in-memory log of cycle-count deltas for named phases
 *        within a single DVFS transition.
 *
 * Filled in by the active DVFS strategy (see
 * @c src/power_manager_hf0_divider.c,
 * @c src/power_manager_pll_retune.c) via
 * @c pm_phase_log_reset() at the start of a transition and repeated
 * @c pm_phase_log_record() calls between the transition's PDL
 * primitives. Dumped by @c pm_phase_log_print() from
 * @c pm_switch_to() right after its aggregate "[pm] transition ..."
 * line, using the same @c effective_hz (MIN of CLK_HF0 pre/post)
 * so per-phase values sum to that aggregate figure.
 *
 * Single-slot: only the most recent transition is stored. That is
 * sufficient because @c pm_switch_to() is the sole consumer and
 * flushes the log right after each call.
 */

#ifndef PM_PHASE_LOG_H_
#define PM_PHASE_LOG_H_

#include <stdint.h>

#ifdef __cplusplus
extern "C" {
#endif

/** Discard any prior record and set the transition label
 *  (printed as "[pm] <label> phases: ..."). @p label must remain
 *  valid until the next @c pm_phase_log_print() call -- pass a
 *  string literal. */
void pm_phase_log_reset(const char *label);

/** Append a named phase.
 *
 *  @param name    Human-readable phase label; must remain valid
 *                 until the next @c pm_phase_log_print(). Pass a
 *                 string literal.
 *  @param cycles  Cortex-M SysTick cycle count elapsed during the
 *                 phase (delta of two @c k_cycle_get_32() reads).
 *  @param hz      CPU frequency the SysTick was ACCUMULATING AT
 *                 during that phase. Must be per-phase because the
 *                 CPU may run at different rates in different
 *                 phases of a single transition (e.g. PLL retune
 *                 goes source-freq -> IHO bypass -> intermediate ->
 *                 IHO bypass -> target). Silently drops entries
 *                 once the internal capacity is exceeded.
 */
void pm_phase_log_record(const char *name, uint32_t cycles, uint32_t hz);

/** Emit one line:
 *    [pm] <label> phases: name1=NNus name2=NNus ... total=NNus
 *  Each phase converts its own cycles to microseconds via its own
 *  recorded @c hz. No-op if the log is empty. */
void pm_phase_log_print(void);

/** Total wall time of the recorded phases, in microseconds.
 *  Computed as sum-of-(cycles / hz) per entry, so it exactly
 *  matches what @c pm_phase_log_print emits as `total=`. Returns 0
 *  if the log is empty. */
uint32_t pm_phase_log_total_us(void);

#ifdef __cplusplus
}
#endif

#endif /* PM_PHASE_LOG_H_ */
```
